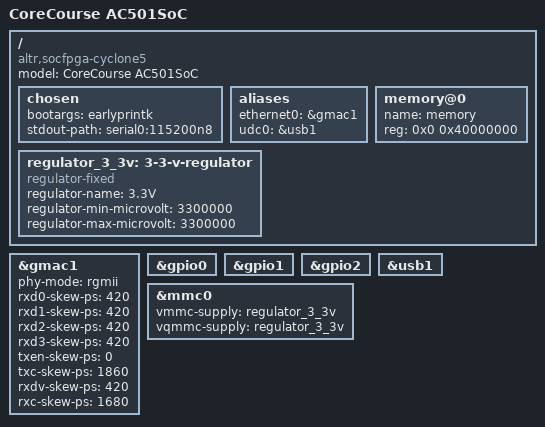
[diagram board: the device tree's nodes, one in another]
// SPDX-License-Identifier: GPL-2.0+
/*
 * Copyright (C) 2025, Brian Sune
 *
 * based on socfpga_cyclone5_socdk.dts
 */

#include "socfpga_cyclone5.dtsi"

/ {
	model = "CoreCourse AC501SoC";
	compatible = "altr,socfpga-cyclone5", "altr,socfpga";

	chosen {
		bootargs = "earlyprintk";
		stdout-path = "serial0:115200n8";
	};

	aliases {
		ethernet0 = &gmac1;
		udc0 = &usb1;
	};

	memory@0 {
		name = "memory";
		device_type = "memory";
		reg = <0x0 0x40000000>; /* 1GB */
	};

	regulator_3_3v: 3-3-v-regulator {
		compatible = "regulator-fixed";
		regulator-name = "3.3V";
		regulator-min-microvolt = <3300000>;
		regulator-max-microvolt = <3300000>;
	};
};

&gmac1 {
	status = "okay";
	phy-mode = "rgmii";

	rxd0-skew-ps = <420>;
	rxd1-skew-ps = <420>;
	rxd2-skew-ps = <420>;
	rxd3-skew-ps = <420>;
	txen-skew-ps = <0>;
	txc-skew-ps = <1860>;
	rxdv-skew-ps = <420>;
	rxc-skew-ps = <1680>;
};

&gpio0 {
	status = "okay";
};

&gpio1 {
	status = "okay";
};

&gpio2 {
	status = "okay";
};

&mmc0 {
	vmmc-supply = <&regulator_3_3v>;
	vqmmc-supply = <&regulator_3_3v>;
	status = "okay";
};

&usb1 {
	status = "okay";
};
